# M369 register map
File version: 0.1
CPU: 
Registers are 32-bit, read-write, reset 0x0 unless marked. A register's access mark holds for its fields unless they carry their own. Offsets are from the block's base; [hi:lo] are bit positions.

## SSP0 — Synchronous Serial Port
Base 0x40040000
Same registers: SSP1 0x40041000, SSP2 0x40042000
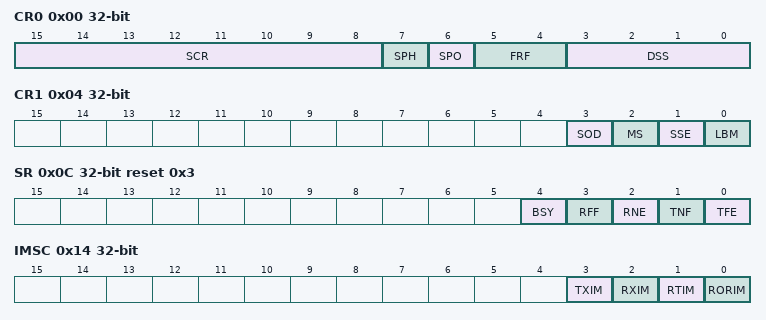
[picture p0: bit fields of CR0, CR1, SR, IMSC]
0x00 CR0 — SSP Control Register 0
  [15:8] SCR, [7] SPH, [6] SPO, [5:4] FRF, [3:0] DSS
0x04 CR1 — SSP Control Register 1
  [3] SOD, [2] MS, [1] SSE, [0] LBM
0x08 DR — SSP Data Register
  [15:0] DATA
0x0C SR ro reset 0x3 — SSP Status Register
  [4] BSY, [3] RFF, [2] RNE, [1] TNF, [0] TFE
0x10 CPSR — SSP Clock Prescaler Register
  [7:0] CPSDVSR
0x14 IMSC — SSP Interrupt Mask Set and Clear Register
  [3] TXIM, [2] RXIM, [1] RTIM, [0] RORIM
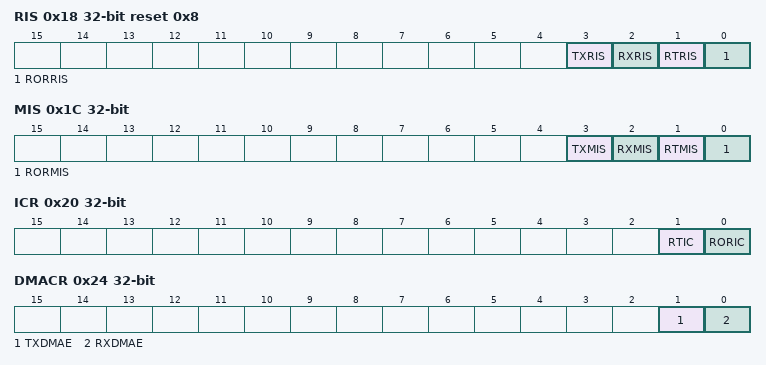
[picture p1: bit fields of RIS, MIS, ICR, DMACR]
0x18 RIS ro reset 0x8 — SSP Raw Interrupt Status Register
  [3] TXRIS, [2] RXRIS, [1] RTRIS, [0] RORRIS
0x1C MIS ro — SSP Masked Interrupt Status Register
  [3] TXMIS, [2] RXMIS, [1] RTMIS, [0] RORMIS
0x20 ICR wo reset not defined — SSP Interrupt Clear Register
  [1] RTIC, [0] RORIC
0x24 DMACR — SSP DMA Control Register
  [1] TXDMAE, [0] RXDMAE

## UART4 — ARM Prime Cell PL011
Base 0x40048000
Same registers: UART5 0x40049000
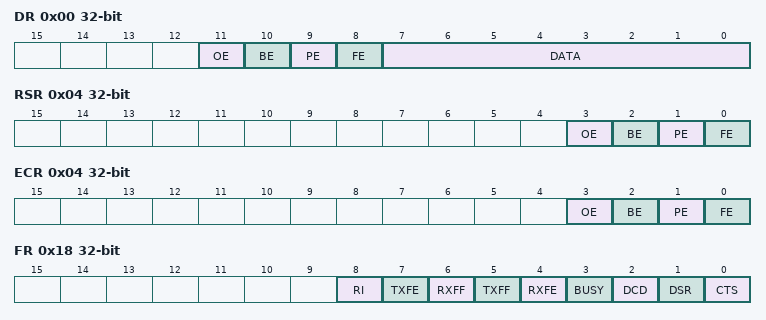
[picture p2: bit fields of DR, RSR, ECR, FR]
0x00 DR — Data Register
  [11] OE, [10] BE, [9] PE, [8] FE, [7:0] DATA
0x04 RSR ro — Receive Status Register
  [3] OE, [2] BE, [1] PE, [0] FE
0x04 ECR wo — Error Clear Register
  [3] OE, [2] BE, [1] PE, [0] FE
0x18 FR — Flag Register
  [8] RI, [7] TXFE, [6] RXFF, [5] TXFF, [4] RXFE, [3] BUSY, [2] DCD, [1] DSR, [0] CTS
0x20 ILPR — IrDA Low-power Counter register
  [7:0] ILPDVSR
0x24 IBDR — Integer Baud Rate Register
  [15:0] BAUDDIVINT
0x28 FBDR — Fractional Baud Rate Register
  [5:0] BAUDDIVFRAC
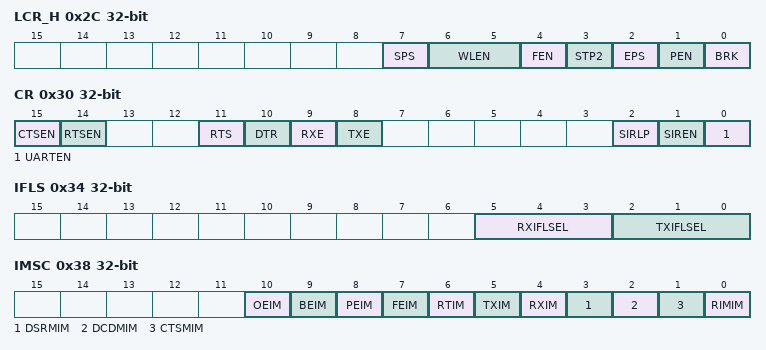
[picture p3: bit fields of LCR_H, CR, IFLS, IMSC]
0x2C LCR_H — Line Control Register
  [7] SPS, [6:5] WLEN, [4] FEN, [3] STP2, [2] EPS, [1] PEN, [0] BRK
0x30 CR — Cntrol Register
  [15] CTSEN, [14] RTSEN, [11] RTS, [10] DTR, [9] RXE, [8] TXE, [2] SIRLP, [1] SIREN, [0] UARTEN
0x34 IFLS — Interrupt FIFO Level Select Register
  [5:3] RXIFLSEL, [2:0] TXIFLSEL
0x38 IMSC — Interrupt Mask set_Clear Register
  [10] OEIM, [9] BEIM, [8] PEIM, [7] FEIM, [6] RTIM, [5] TXIM, [4] RXIM, [3] DSRMIM, [2] DCDMIM, [1] CTSMIM, [0] RIMIM
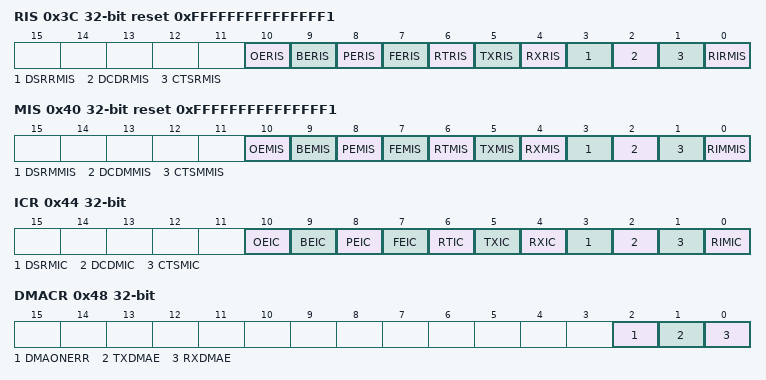
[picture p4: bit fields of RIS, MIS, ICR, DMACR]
0x3C RIS ro reset 0xFFFFFFFFFFFFFFF1 — Raw Interrupt Status Register
  [10] OERIS, [9] BERIS, [8] PERIS, [7] FERIS, [6] RTRIS, [5] TXRIS, [4] RXRIS, [3] DSRRMIS, [2] DCDRMIS, [1] CTSRMIS, [0] RIRMIS
0x40 MIS ro reset 0xFFFFFFFFFFFFFFF1 — Masked Interrupt Status Register
  [10] OEMIS, [9] BEMIS, [8] PEMIS, [7] FEMIS, [6] RTMIS, [5] TXMIS, [4] RXMIS, [3] DSRMMIS, [2] DCDMMIS, [1] CTSMMIS, [0] RIMMIS
0x44 ICR wo — Interrupt Clear Register
  [10] OEIC, [9] BEIC, [8] PEIC, [7] FEIC, [6] RTIC, [5] TXIC, [4] RXIC, [3] DSRMIC, [2] DCDMIC, [1] CTSMIC, [0] RIMIC
0x48 DMACR — DMA Control Register
  [2] DMAONERR, [1] TXDMAE, [0] RXDMAE

## DMAA — DMA Controller
Base 0x4004C000
Same registers: DMAB 0x4004D000
0x00 STATUS ro reset 0x101F0000 — DMA Status Register
  [0] MASTER_ENABLE
0x04 CFG wo reset not defined — DMA Configuration Register
  [0] MASTER_ENABLE
0x08 CTRLBASEPTR — DMA Control Data Base Pointer Register
  [31:10] CTRL_BASE_PTR
0x0C ALTCTRLBASEPTR ro — DMA Channel Alternate Control Data Base Pointer Register
  [31:0] ALT_CTRL_BASE_PTR
0x14 CHNLSWREQUEST wo reset not defined — DMA Channel Software Request Register
  [31:0] CHNL_SW_REQUEST
0x18 CHNLUSEBURSTSET — DMA Channel Useburst Set Register
  [31:0] CHNL_USEBURST_SET
0x1C CHNLUSEBURSTCLR wo reset not defined — DMA Channel Useburst Clear Register
  [31:0] CHNL_USEBURST_CLR
0x20 CHNLREQMASKSET — DMA Channel Request Mask Set Register
  [31:0] CHNL_REQ_MASK_SET
0x24 CHNLREQMASKCLR wo reset not defined — DMA Channel Request Mask Clear Register
  [31:0] CHNL_REQ_MASK_CLR
0x28 CHNLENABLESET — DMA Channel Enable Set Register
  [31:0] CHNL_ENABLE_SET
0x2C CHNLENABLECLR wo reset not defined — DMA Channel Enable Clear Register
  [31:0] CHNL_ENABLE_CLR
0x30 CHNLPRIALTSET — DMA Channel Primary-Alternate Set Register
  [31:0] CHNL_PRI_ALT_SET
0x34 CHNLPRIALTCLR wo reset not defined — DMA Channel Primary-Alternate Clear Register
  [31:0] CHNL_PRI_ALT_CLR
0x38 CHNLPRIORITYSET — DMA Channel Priority Set Register
  [31:0] CHNL_PRIORITY_SET
0x3C CHNLPRIORITYCLR wo reset not defined — DMA Channel Priority Clear Register
  [31:0] CHNL_PRIORITY_CLR
0x4C ERRCLR — DMA Bus Error Clear Register
  [0] ERR_CLR
